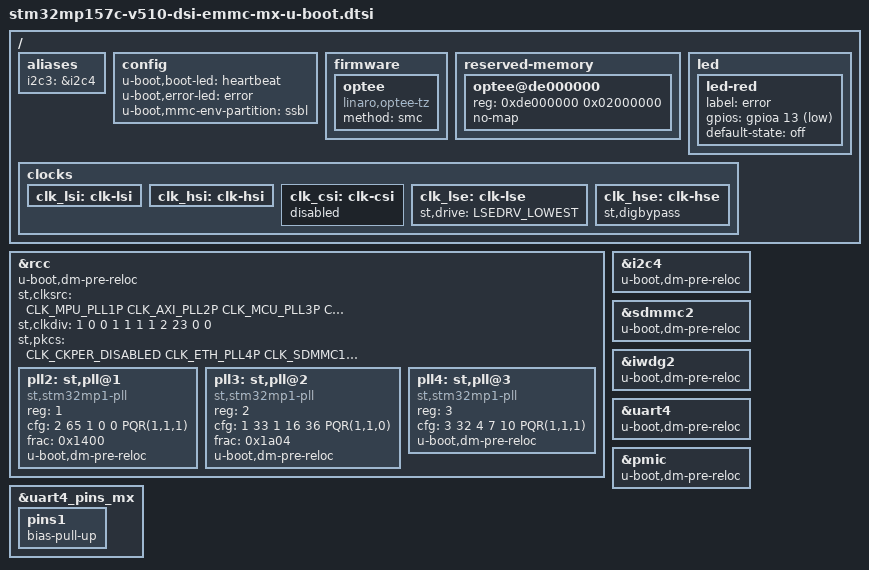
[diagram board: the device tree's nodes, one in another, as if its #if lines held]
/* SPDX-License-Identifier: GPL-2.0+ OR BSD-3-Clause*/
/*
 * Copyright (C) 2022, STMicroelectronics - All Rights Reserved
 * Author: STM32CubeMX code generation for STMicroelectronics.
 */

/* For more information on Device Tree configuration, please refer to
 * https://wiki.st.com/stm32mpu/wiki/Category:Device_tree_configuration
 */

#include <dt-bindings/clock/stm32mp1-clksrc.h>
#include "stm32mp15-mx.dtsi"

#include "stm32mp15-u-boot.dtsi"
#include "stm32mp15-ddr.dtsi"

/* USER CODE BEGIN includes */
/* USER CODE END includes */

/ {

	/* USER CODE BEGIN root */

	aliases{
		i2c3 = &i2c4;
	};

	config{
		u-boot,boot-led = "heartbeat";
		u-boot,error-led = "error";
		u-boot,mmc-env-partition = "fip";
	};

#ifdef CONFIG_STM32MP15x_STM32IMAGE

	config{
		u-boot,mmc-env-partition = "ssbl";
	};

	firmware{

		optee{
			compatible = "linaro,optee-tz";
			method = "smc";
		};
	};

	reserved-memory{

		optee@de000000{
			reg = <0xde000000 0x02000000>;
			no-map;
		};
	};
#endif

	led{

		led-red{
			label = "error";
			gpios = <&gpioa 13 GPIO_ACTIVE_LOW>;
			default-state = "off";
			status = "okay";
		};
	};
	/* USER CODE END root */

	clocks {
		/* USER CODE BEGIN clocks */
		/* USER CODE END clocks */

#ifndef CONFIG_TFABOOT
		clk_lsi: clk-lsi {

			/* USER CODE BEGIN clk_lsi */
			/* USER CODE END clk_lsi */
		};
		clk_hsi: clk-hsi {

			/* USER CODE BEGIN clk_hsi */
			/* USER CODE END clk_hsi */
		};
		clk_csi: clk-csi {
			status = "disabled";

			/* USER CODE BEGIN clk_csi */
			/* USER CODE END clk_csi */
		};
		clk_lse: clk-lse {
			st,drive = < LSEDRV_LOWEST >;

			/* USER CODE BEGIN clk_lse */
			/* USER CODE END clk_lse */
		};
		clk_hse: clk-hse {
			st,digbypass;

			/* USER CODE BEGIN clk_hse */
			/* USER CODE END clk_hse */
		};
#endif	/*CONFIG_TFABOOT*/
	};

}; /*root*/

#ifndef CONFIG_TFABOOT

&rcc{
	u-boot,dm-pre-reloc;
	st,clksrc = <
		CLK_MPU_PLL1P
		CLK_AXI_PLL2P
		CLK_MCU_PLL3P
		CLK_PLL12_HSE
		CLK_PLL3_HSE
		CLK_PLL4_HSE
		CLK_RTC_LSE
		CLK_MCO1_DISABLED
		CLK_MCO2_DISABLED
	>;
	st,clkdiv = <
		1 		/*MPU*/
		0 		/*AXI*/
		0 		/*MCU*/
		1 		/*APB1*/
		1 		/*APB2*/
		1 		/*APB3*/
		1 		/*APB4*/
		2 		/*APB5*/
		23 		/*RTC*/
		0 		/*MCO1*/
		0 		/*MCO2*/
	>;
	st,pkcs = <
		CLK_CKPER_DISABLED
		CLK_ETH_PLL4P
		CLK_SDMMC12_PLL4P
		CLK_DSI_DSIPLL
		CLK_STGEN_HSE
		CLK_USBPHY_HSE
		CLK_SPI2S1_DISABLED
		CLK_SPI2S23_PLL3Q
		CLK_SPI45_DISABLED
		CLK_SPI6_DISABLED
		CLK_I2C46_HSI
		CLK_SDMMC3_DISABLED
		CLK_USBO_USBPHY
		CLK_ADC_DISABLED
		CLK_CEC_DISABLED
		CLK_I2C12_DISABLED
		CLK_I2C35_DISABLED
		CLK_UART1_DISABLED
		CLK_UART24_HSI
		CLK_UART35_PCLK1
		CLK_UART6_DISABLED
		CLK_UART78_PCLK1
		CLK_SPDIF_DISABLED
		CLK_SAI1_DISABLED
		CLK_SAI2_PLL3Q
		CLK_SAI3_DISABLED
		CLK_SAI4_DISABLED
		CLK_RNG1_LSI
		CLK_LPTIM1_DISABLED
		CLK_LPTIM23_PCLK3
		CLK_LPTIM45_DISABLED
	>;
	pll2:st,pll@1 {
		compatible = "st,stm32mp1-pll";
		reg = <1>;
		cfg = < 2 65 1 0 0 PQR(1,1,1) >;
		frac = < 0x1400 >;
		u-boot,dm-pre-reloc;
	};
	pll3:st,pll@2 {
		compatible = "st,stm32mp1-pll";
		reg = <2>;
		cfg = < 1 33 1 16 36 PQR(1,1,0) >;
		frac = < 0x1a04 >;
		u-boot,dm-pre-reloc;
	};
	pll4:st,pll@3 {
		compatible = "st,stm32mp1-pll";
		reg = <3>;
		cfg = < 3 32 4 7 10 PQR(1,1,1) >;
		u-boot,dm-pre-reloc;
	};

	/* USER CODE BEGIN rcc */
	/* USER CODE END rcc */
};

&i2c4{
	u-boot,dm-pre-reloc;

	/* USER CODE BEGIN i2c4 */
	/* USER CODE END i2c4 */
};

&sdmmc2{
	u-boot,dm-pre-reloc;

	/* USER CODE BEGIN sdmmc2 */
	/* USER CODE END sdmmc2 */
};

#endif	/*CONFIG_TFABOOT*/


&iwdg2{
	u-boot,dm-pre-reloc;

	/* USER CODE BEGIN iwdg2 */
	/* USER CODE END iwdg2 */
};

&uart4{
	u-boot,dm-pre-reloc;

	/* USER CODE BEGIN uart4 */
	/* USER CODE END uart4 */
};



/* USER CODE BEGIN addons */


#ifndef CONFIG_TFABOOT

&pmic{
	u-boot,dm-pre-reloc;
};

#endif /*CONFIG_TFABOOT*/

&uart4_pins_mx {
	pins1 {	/* UART4_RX */
		/* pull-up on rx to avoid floating level */
		bias-pull-up;
	};
};
/* USER CODE END addons */

